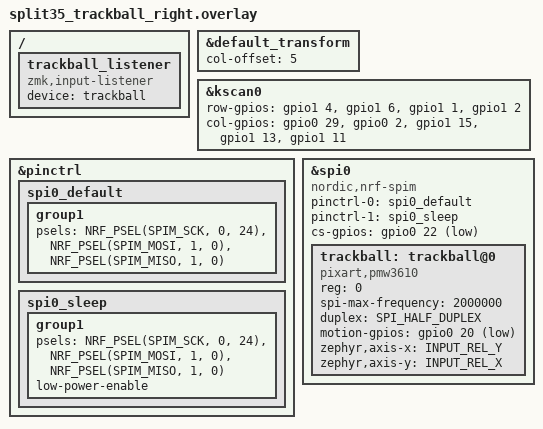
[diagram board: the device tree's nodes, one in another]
#include "split35_trackball.dtsi"
#include <zephyr/dt-bindings/input/input-event-codes.h>
#include <zephyr/dt-bindings/spi/spi.h>

&default_transform {
    col-offset = <5>;
};

&kscan0 {
    row-gpios
        = <&gpio1  4 (GPIO_ACTIVE_HIGH | GPIO_PULL_DOWN)>,
          <&gpio1  6 (GPIO_ACTIVE_HIGH | GPIO_PULL_DOWN)>,
          <&gpio1  1 (GPIO_ACTIVE_HIGH | GPIO_PULL_DOWN)>,
          <&gpio1  2 (GPIO_ACTIVE_HIGH | GPIO_PULL_DOWN)>;

    col-gpios
        = <&gpio0 29 GPIO_ACTIVE_HIGH>,
          <&gpio0  2 GPIO_ACTIVE_HIGH>,
          <&gpio1 15 GPIO_ACTIVE_HIGH>,
          <&gpio1 13 GPIO_ACTIVE_HIGH>,
          <&gpio1 11 GPIO_ACTIVE_HIGH>;
};

&pinctrl {
    spi0_default: spi0_default {
        group1 {
            psels = <NRF_PSEL(SPIM_SCK, 0, 24)>,
                    <NRF_PSEL(SPIM_MOSI, 1, 0)>,
                    <NRF_PSEL(SPIM_MISO, 1, 0)>;
        };
    };

    spi0_sleep: spi0_sleep {
        group1 {
            psels = <NRF_PSEL(SPIM_SCK, 0, 24)>,
                    <NRF_PSEL(SPIM_MOSI, 1, 0)>,
                    <NRF_PSEL(SPIM_MISO, 1, 0)>;
            low-power-enable;
        };
    };
};

&spi0 {
    status = "okay";
    compatible = "nordic,nrf-spim";
    pinctrl-0 = <&spi0_default>;
    pinctrl-1 = <&spi0_sleep>;
    pinctrl-names = "default", "sleep";
    cs-gpios = <&gpio0 22 GPIO_ACTIVE_LOW>;

    trackball: trackball@0 {
        status = "okay";
        compatible = "pixart,pmw3610";
        reg = <0>;
        spi-max-frequency = <2000000>;
        duplex = <SPI_HALF_DUPLEX>;
        motion-gpios = <&gpio0 20 (GPIO_ACTIVE_LOW | GPIO_PULL_UP)>;
        zephyr,axis-x = <INPUT_REL_Y>;
        zephyr,axis-y = <INPUT_REL_X>;
    };
};

/ {
    trackball_listener {
        compatible = "zmk,input-listener";
        device = <&trackball>;
    };
};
